AUTOSAR XML (schema 4-2-2)
package /AUTOLIV/SoftwareComponents/SFR
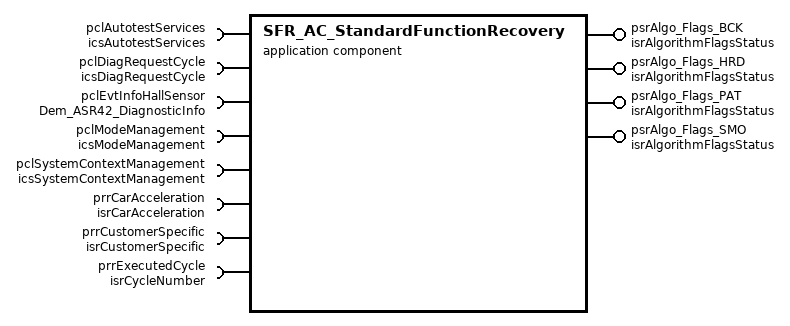
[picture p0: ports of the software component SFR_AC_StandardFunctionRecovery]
  application sw component type SFR_AC_StandardFunctionRecovery: category=SWC
    8 x require port:
      pclAutotestServices: required-com-specs=[GetTestResult, GetLastCriticalAutotestID], required-interface=icsAutotestServices
      pclDiagRequestCycle: required-com-specs=[GetDiagRequestCycle, ClearDiagRequestCycle], required-interface=icsDiagRequestCycle
      pclEvtInfoHallSensor: required-interface=Dem_ASR42_DiagnosticInfo
        required-com-specs:
          GetEventStatus
          GetEventFailed
          GetEventTested
          GetDTCOfEvent
          GetFaultDetectionCounter
          GetEventFreezeFrameData
          GetEventExtendedDataRecord
      pclModeManagement: client-com-spec=CheckModeStatus, required-interface=icsModeManagement
      pclSystemContextManagement: required-interface=icsSystemContextManagement
        required-com-specs:
          GetLastTensionningState
          RestoreSystemContext
          GetLastKL30LostStatus
          SuperviseKL30bg
          ManageSystemContextStorage
      prrCarAcceleration: nonqueued-receiver-com-spec{data-element=b8IsCarAccelerationLow, uses-end-to-end-protection=0, init-value=constant-reference=APPLINIT_KB8_CAR_ACCEL_LOW_TRUE}, required-interface=isrCarAcceleration
      prrCustomerSpecific: required-interface=isrCustomerSpecific
        required-com-specs:
          data-element=b8IsCarCrashDetected, uses-end-to-end-protection=0, init-value=constant-reference=APPLINIT_KB8_CAR_CRASH_DETECTED_FALSE
          data-element=b8IsCarCrankingActive, uses-end-to-end-protection=0, init-value=constant-reference=APPLINIT_KB8_CAR_CRANKING_ACTIVE_TRUE
          data-element=u8BeltSlackStatus, uses-end-to-end-protection=0, init-value=constant-reference=APPLINIT_KU8_BELT_SLACK_STATUS_NOT_DEFINED
          data-element=u8PreCrashRequest, uses-end-to-end-protection=0, init-value=constant-reference=APPLINIT_KU8_PRE_CRASH_REQUEST_NO_REQUEST
          data-element=b8PreCrashRequestEnable, uses-end-to-end-protection=0, init-value=constant-reference=APPLINIT_KB8_BOOLEAN_FALSE
          data-element=u8HapticRequest, uses-end-to-end-protection=0, init-value=constant-reference=APPLINIT_KU8_HAPTIC_REQUEST_NO
      prrExecutedCycle: nonqueued-receiver-com-spec{data-element=u8CycleNumber, uses-end-to-end-protection=0, init-value=constant-reference=APPLINIT_KU8_CYCLE_NUMBER_NONE}, required-interface=isrCycleNumber
    4 x provide port, all with provided-interface=isrAlgorithmFlagsStatus:
      psrAlgo_Flags_BCK
        provided-com-specs:
          data-element=b8InterruptFlag, uses-end-to-end-protection=0, init-value=constant-reference=APPLINIT_KB8_ALGO_FLAG_FALSE
          data-element=b8PreConditionsFlag, uses-end-to-end-protection=1, init-value=constant-reference=APPLINIT_KB8_ALGO_FLAG_FALSE
          data-element=b8PreActivationFlag, uses-end-to-end-protection=1, init-value=constant-reference=APPLINIT_KB8_ALGO_FLAG_FALSE
          data-element=b8TriggerFlag, uses-end-to-end-protection=1, init-value=constant-reference=APPLINIT_KB8_ALGO_FLAG_FALSE
          data-element=u8TriggeringSource, uses-end-to-end-protection=1, init-value=constant-reference=APPLINIT_KU8_TRIGGERING_SOURCE_NO
      psrAlgo_Flags_HRD
        provided-com-specs:
          data-element=b8TriggerFlag, uses-end-to-end-protection=1, init-value=constant-reference=APPLINIT_KB8_ALGO_FLAG_FALSE
          data-element=b8PreActivationFlag, uses-end-to-end-protection=1, init-value=constant-reference=APPLINIT_KB8_ALGO_FLAG_FALSE
          data-element=b8PreConditionsFlag, uses-end-to-end-protection=1, init-value=constant-reference=APPLINIT_KB8_ALGO_FLAG_FALSE
          data-element=b8InterruptFlag, uses-end-to-end-protection=1, init-value=constant-reference=APPLINIT_KB8_ALGO_FLAG_FALSE
          data-element=u8TriggeringSource, uses-end-to-end-protection=1, init-value=constant-reference=APPLINIT_KU8_TRIGGERING_SOURCE_NO
      psrAlgo_Flags_PAT
        provided-com-specs:
          data-element=b8TriggerFlag, uses-end-to-end-protection=1, init-value=constant-reference=APPLINIT_KB8_ALGO_FLAG_FALSE
          data-element=b8PreActivationFlag, uses-end-to-end-protection=1, init-value=constant-reference=APPLINIT_KB8_ALGO_FLAG_FALSE
          data-element=b8InterruptFlag, uses-end-to-end-protection=1, init-value=constant-reference=APPLINIT_KB8_ALGO_FLAG_FALSE
          data-element=u8TriggeringSource, uses-end-to-end-protection=1, init-value=constant-reference=APPLINIT_KU8_TRIGGERING_SOURCE_NO
          data-element=b8PreConditionsFlag, uses-end-to-end-protection=1, init-value=constant-reference=APPLINIT_KB8_ALGO_FLAG_FALSE
      psrAlgo_Flags_SMO
        provided-com-specs:
          data-element=b8PreConditionsFlag, uses-end-to-end-protection=1, init-value=constant-reference=APPLINIT_KB8_ALGO_FLAG_FALSE
          data-element=u8TriggeringSource, uses-end-to-end-protection=1, init-value=constant-reference=APPLINIT_KU8_TRIGGERING_SOURCE_NO
          data-element=b8TriggerFlag, uses-end-to-end-protection=1, init-value=constant-reference=APPLINIT_KB8_ALGO_FLAG_FALSE
          data-element=b8InterruptFlag, uses-end-to-end-protection=1, init-value=constant-reference=APPLINIT_KB8_ALGO_FLAG_FALSE
          data-element=b8PreActivationFlag, uses-end-to-end-protection=1, init-value=constant-reference=APPLINIT_KB8_ALGO_FLAG_FALSE
